# HDSC_HC32F4A0 register map
Vendor: HDSC Co.,Ltd.; Series: ARMCM4; File version: 1.0
CPU: CM4 r0p1, little endian, MPU, FPU, 4 interrupt priority bits
Registers are 32-bit, read-write, reset 0x0 unless marked. A register's access mark holds for its fields unless they carry their own. Offsets are from the block's base; [hi:lo] are bit positions; {n}, {i} and the like mark numbered series.

## EMBG0
Base 0x40017C00
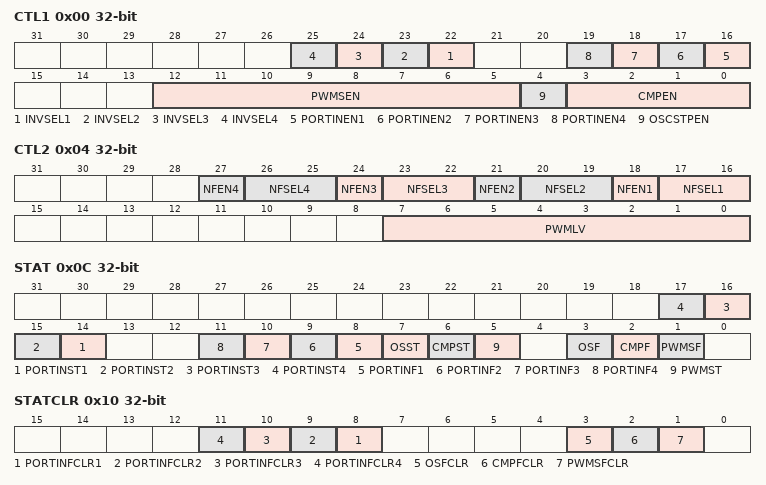
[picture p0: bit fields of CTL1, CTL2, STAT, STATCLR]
0x00 CTL1
  [n+21] INVSEL{n} (n=1..4), [n+15] PORTINEN{n} (n=1..4), [12:5] PWMSEN, [4] OSCSTPEN, [3:0] CMPEN
0x04 CTL2
  [3n+15] NFEN{n} (n=1..4), [3n+14:3n+13] NFSEL{n} (n=1..4), [7:0] PWMLV
0x08 SOE
  [0] SOE
0x0C STAT ro
  [n+13] PORTINST{n} (n=1..4), [n+7] PORTINF{n} (n=1..4), [7] OSST, [6] CMPST, [5] PWMST, [3] OSF, [2] CMPF, [1] PWMSF
0x10 STATCLR wo
  [n+7] PORTINFCLR{n} (n=1..4), [3] OSFCLR, [2] CMPFCLR, [1] PWMSFCLR
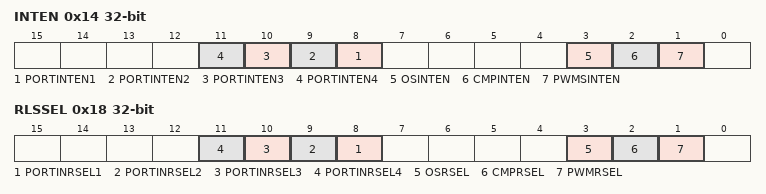
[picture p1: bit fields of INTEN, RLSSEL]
0x14 INTEN
  [n+7] PORTINTEN{n} (n=1..4), [3] OSINTEN, [2] CMPINTEN, [1] PWMSINTEN
0x18 RLSSEL
  [n+7] PORTINRSEL{n} (n=1..4), [3] OSRSEL, [2] CMPRSEL, [1] PWMRSEL

## EMBG1
Base 0x40017C00; alternate view of EMBG0
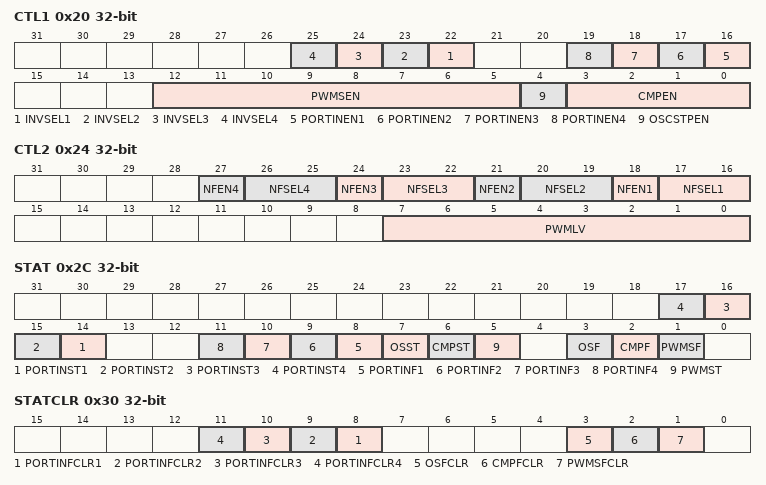
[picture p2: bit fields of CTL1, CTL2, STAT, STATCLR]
0x20 CTL1
  [n+21] INVSEL{n} (n=1..4), [n+15] PORTINEN{n} (n=1..4), [12:5] PWMSEN, [4] OSCSTPEN, [3:0] CMPEN
0x24 CTL2
  [3n+15] NFEN{n} (n=1..4), [3n+14:3n+13] NFSEL{n} (n=1..4), [7:0] PWMLV
0x28 SOE
  [0] SOE
0x2C STAT ro
  [n+13] PORTINST{n} (n=1..4), [n+7] PORTINF{n} (n=1..4), [7] OSST, [6] CMPST, [5] PWMST, [3] OSF, [2] CMPF, [1] PWMSF
0x30 STATCLR wo
  [n+7] PORTINFCLR{n} (n=1..4), [3] OSFCLR, [2] CMPFCLR, [1] PWMSFCLR
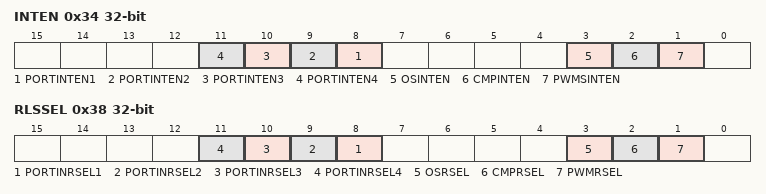
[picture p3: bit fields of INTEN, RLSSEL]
0x34 INTEN
  [n+7] PORTINTEN{n} (n=1..4), [3] OSINTEN, [2] CMPINTEN, [1] PWMSINTEN
0x38 RLSSEL
  [n+7] PORTINRSEL{n} (n=1..4), [3] OSRSEL, [2] CMPRSEL, [1] PWMRSEL

## EMBG2
Base 0x40017C00; alternate view of EMBG0
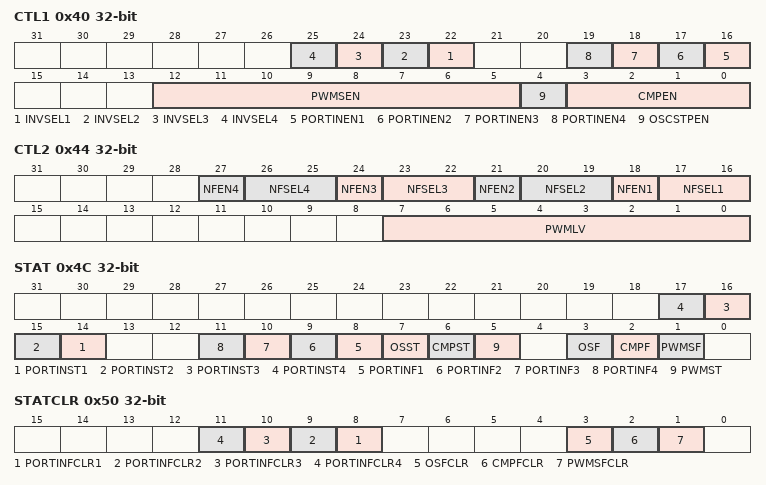
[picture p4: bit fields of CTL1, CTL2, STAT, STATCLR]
0x40 CTL1
  [n+21] INVSEL{n} (n=1..4), [n+15] PORTINEN{n} (n=1..4), [12:5] PWMSEN, [4] OSCSTPEN, [3:0] CMPEN
0x44 CTL2
  [3n+15] NFEN{n} (n=1..4), [3n+14:3n+13] NFSEL{n} (n=1..4), [7:0] PWMLV
0x48 SOE
  [0] SOE
0x4C STAT ro
  [n+13] PORTINST{n} (n=1..4), [n+7] PORTINF{n} (n=1..4), [7] OSST, [6] CMPST, [5] PWMST, [3] OSF, [2] CMPF, [1] PWMSF
0x50 STATCLR wo
  [n+7] PORTINFCLR{n} (n=1..4), [3] OSFCLR, [2] CMPFCLR, [1] PWMSFCLR
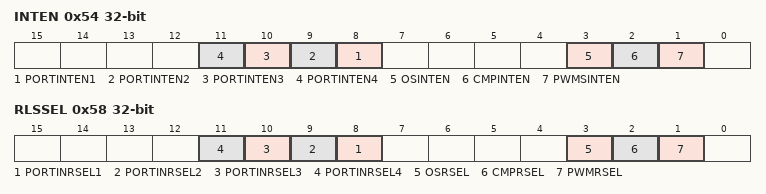
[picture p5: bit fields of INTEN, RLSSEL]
0x54 INTEN
  [n+7] PORTINTEN{n} (n=1..4), [3] OSINTEN, [2] CMPINTEN, [1] PWMSINTEN
0x58 RLSSEL
  [n+7] PORTINRSEL{n} (n=1..4), [3] OSRSEL, [2] CMPRSEL, [1] PWMRSEL

## EMBG3
Base 0x40017C00; alternate view of EMBG0
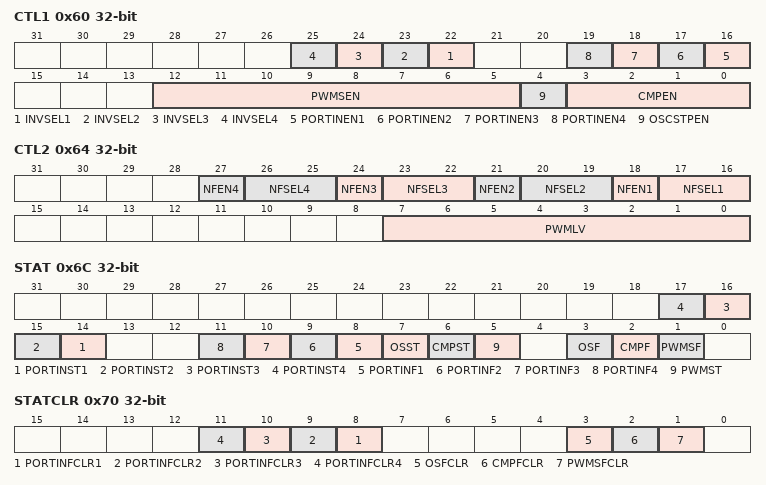
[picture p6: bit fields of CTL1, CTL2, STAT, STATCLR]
0x60 CTL1
  [n+21] INVSEL{n} (n=1..4), [n+15] PORTINEN{n} (n=1..4), [12:5] PWMSEN, [4] OSCSTPEN, [3:0] CMPEN
0x64 CTL2
  [3n+15] NFEN{n} (n=1..4), [3n+14:3n+13] NFSEL{n} (n=1..4), [7:0] PWMLV
0x68 SOE
  [0] SOE
0x6C STAT ro
  [n+13] PORTINST{n} (n=1..4), [n+7] PORTINF{n} (n=1..4), [7] OSST, [6] CMPST, [5] PWMST, [3] OSF, [2] CMPF, [1] PWMSF
0x70 STATCLR wo
  [n+7] PORTINFCLR{n} (n=1..4), [3] OSFCLR, [2] CMPFCLR, [1] PWMSFCLR
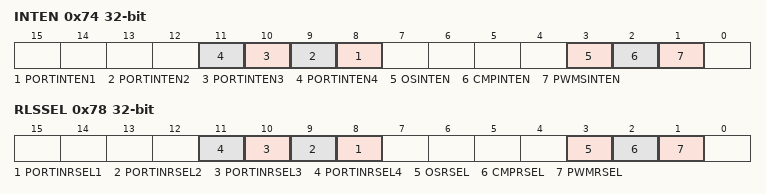
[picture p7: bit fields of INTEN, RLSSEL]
0x74 INTEN
  [n+7] PORTINTEN{n} (n=1..4), [3] OSINTEN, [2] CMPINTEN, [1] PWMSINTEN
0x78 RLSSEL
  [n+7] PORTINRSEL{n} (n=1..4), [3] OSRSEL, [2] CMPRSEL, [1] PWMRSEL

## EMBG4
Base 0x40017C00; alternate view of EMBG0
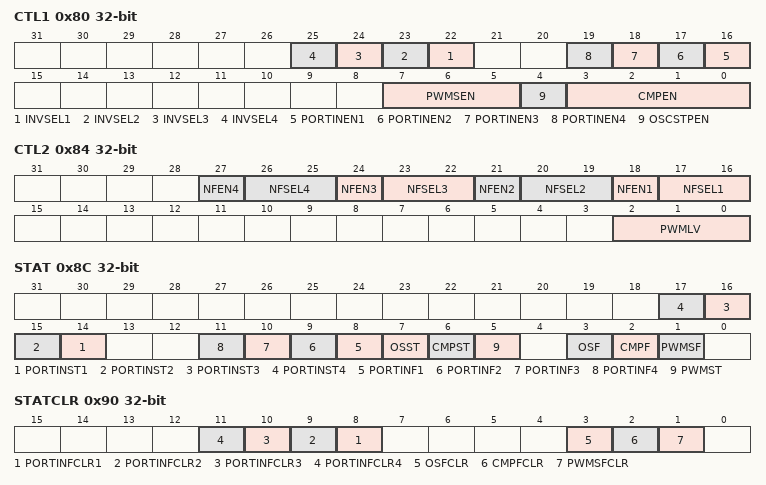
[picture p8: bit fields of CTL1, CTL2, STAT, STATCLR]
0x80 CTL1
  [n+21] INVSEL{n} (n=1..4), [n+15] PORTINEN{n} (n=1..4), [7:5] PWMSEN, [4] OSCSTPEN, [3:0] CMPEN
0x84 CTL2
  [3n+15] NFEN{n} (n=1..4), [3n+14:3n+13] NFSEL{n} (n=1..4), [2:0] PWMLV
0x88 SOE
  [0] SOE
0x8C STAT ro
  [n+13] PORTINST{n} (n=1..4), [n+7] PORTINF{n} (n=1..4), [7] OSST, [6] CMPST, [5] PWMST, [3] OSF, [2] CMPF, [1] PWMSF
0x90 STATCLR wo
  [n+7] PORTINFCLR{n} (n=1..4), [3] OSFCLR, [2] CMPFCLR, [1] PWMSFCLR
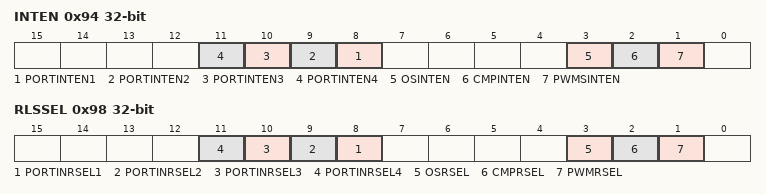
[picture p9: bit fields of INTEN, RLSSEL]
0x94 INTEN
  [n+7] PORTINTEN{n} (n=1..4), [3] OSINTEN, [2] CMPINTEN, [1] PWMSINTEN
0x98 RLSSEL
  [n+7] PORTINRSEL{n} (n=1..4), [3] OSRSEL, [2] CMPRSEL, [1] PWMRSEL

## EMBG5
Base 0x40017C00; alternate view of EMBG0
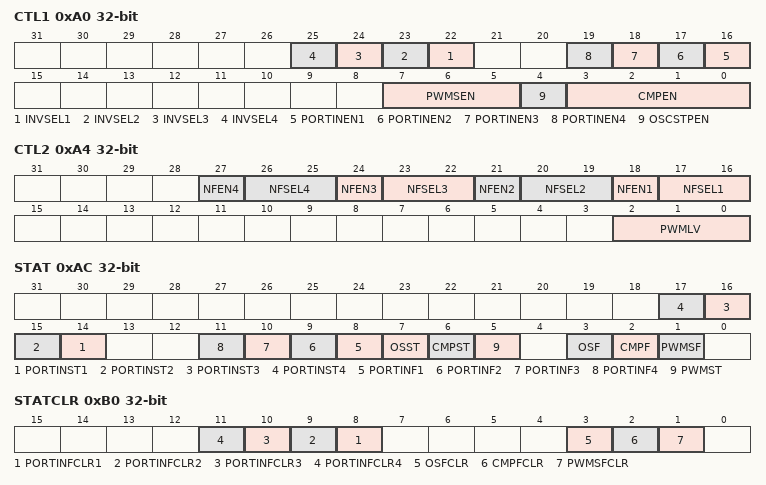
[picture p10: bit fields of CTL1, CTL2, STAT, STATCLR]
0xA0 CTL1
  [n+21] INVSEL{n} (n=1..4), [n+15] PORTINEN{n} (n=1..4), [7:5] PWMSEN, [4] OSCSTPEN, [3:0] CMPEN
0xA4 CTL2
  [3n+15] NFEN{n} (n=1..4), [3n+14:3n+13] NFSEL{n} (n=1..4), [2:0] PWMLV
0xA8 SOE
  [0] SOE
0xAC STAT ro
  [n+13] PORTINST{n} (n=1..4), [n+7] PORTINF{n} (n=1..4), [7] OSST, [6] CMPST, [5] PWMST, [3] OSF, [2] CMPF, [1] PWMSF
0xB0 STATCLR wo
  [n+7] PORTINFCLR{n} (n=1..4), [3] OSFCLR, [2] CMPFCLR, [1] PWMSFCLR
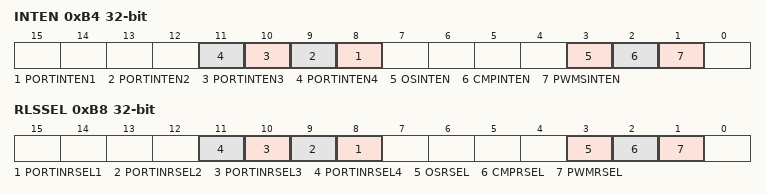
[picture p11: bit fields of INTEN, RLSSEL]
0xB4 INTEN
  [n+7] PORTINTEN{n} (n=1..4), [3] OSINTEN, [2] CMPINTEN, [1] PWMSINTEN
0xB8 RLSSEL
  [n+7] PORTINRSEL{n} (n=1..4), [3] OSRSEL, [2] CMPRSEL, [1] PWMRSEL
